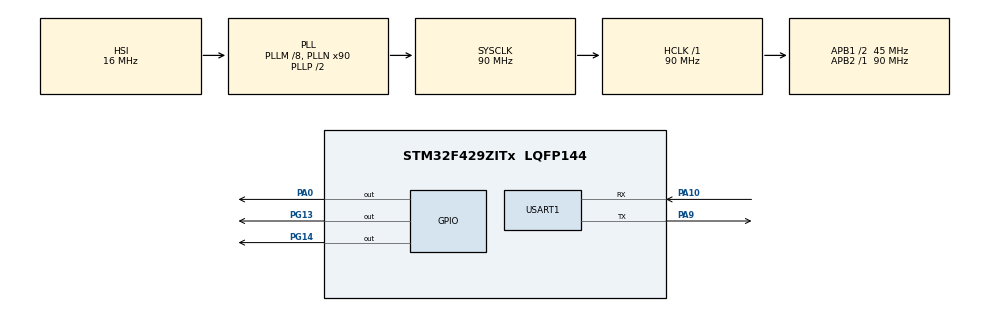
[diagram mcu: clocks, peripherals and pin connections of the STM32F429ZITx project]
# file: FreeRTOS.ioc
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FREERTOS.Queues01=myQueue01,16,uint16_t,0,Dynamic,NULL,NULL
FREERTOS.Tasks01=defaultTask,25,128,StartDefaultTask,Default,NULL,Dynamic,NULL,NULL;myTask,24,128,StartTask02,Default,NULL,Dynamic,NULL,NULL;myTask03,24,128,StartTask03,Default,NULL,Dynamic,NULL,NULL
Mcu.Family=STM32F4
Mcu.Name=STM32F429ZITx
Mcu.Package=LQFP144
NVIC.PriorityGroup=NVIC_PRIORITYGROUP_4
NVIC.TIM6_DAC_IRQn=true\:15\:0\:false\:false\:true\:false\:false\:true\:true
NVIC.TimeBase=TIM6_DAC_IRQn
NVIC.TimeBaseIP=TIM6
PA0/WKUP.Signal=GPIO_Output
PA10.Mode=Asynchronous
PA10.Signal=USART1_RX
PA9.Mode=Asynchronous
PA9.Signal=USART1_TX
PG13.Signal=GPIO_Output
PG14.Signal=GPIO_Output
PH0/OSC_IN.Mode=HSE-External-Oscillator
PH0/OSC_IN.Signal=RCC_OSC_IN
PH1/OSC_OUT.Mode=HSE-External-Oscillator
PH1/OSC_OUT.Signal=RCC_OSC_OUT
ProjectManager.HeapSize=0x200
ProjectManager.StackSize=0x400
ProjectManager.TargetToolchain=STM32CubeIDE
RCC.48MHZClocksFreq_Value=45000000
RCC.AHBFreq_Value=90000000
RCC.APB1CLKDivider=RCC_HCLK_DIV2
RCC.APB1Freq_Value=45000000
RCC.APB1TimFreq_Value=90000000
RCC.APB2Freq_Value=90000000
RCC.APB2TimFreq_Value=90000000
RCC.CortexFreq_Value=90000000
RCC.HCLKFreq_Value=90000000
RCC.HSE_VALUE=25000000
RCC.HSI_VALUE=16000000
RCC.LSE_VALUE=32768
RCC.PLLM=8
RCC.PLLN=90
RCC.SYSCLKFreq_VALUE=90000000
RCC.SYSCLKSource=RCC_SYSCLKSOURCE_PLLCLK
RCC.VCOOutputFreq_Value=180000000
USART1.VirtualMode=VM_ASYNC
VP_FREERTOS_VS_CMSIS_V2.Mode=CMSIS_V2
VP_SYS_VS_tim6.Mode=TIM6
board=custom

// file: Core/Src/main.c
/* USER CODE BEGIN Header */
/**
  ******************************************************************************
  * @file           : main.c
  * @brief          : Main program body
  ******************************************************************************
  * @attention
  *
  * Copyright (c) 2025 STMicroelectronics.
  * All rights reserved.
  *
  * This software is licensed under terms that can be found in the LICENSE file
  * in the root directory of this software component.
  * If no LICENSE file comes with this software, it is provided AS-IS.
  *
  ******************************************************************************
  */
/* USER CODE END Header */
#include "main.h"
#include "cmsis_os.h"

UART_HandleTypeDef huart1;

/* Definitions for defaultTask */
osThreadId_t defaultTaskHandle;
const osThreadAttr_t defaultTask_attributes = {
  .name = "defaultTask",
  .stack_size = 128 * 4,
  .priority = (osPriority_t) osPriorityNormal1,
};
/* Definitions for myTask */
osThreadId_t myTaskHandle;
const osThreadAttr_t myTask_attributes = {
  .name = "myTask",
  .stack_size = 128 * 4,
  .priority = (osPriority_t) osPriorityNormal,
};
/* Definitions for myTask03 */
osThreadId_t myTask03Handle;
const osThreadAttr_t myTask03_attributes = {
  .name = "myTask03",
  .stack_size = 128 * 4,
  .priority = (osPriority_t) osPriorityNormal,
};
/* Definitions for myQueue01 */
osMessageQueueId_t myQueue01Handle;
const osMessageQueueAttr_t myQueue01_attributes = {
  .name = "myQueue01"
};

void SystemClock_Config(void);
static void MX_GPIO_Init(void);
static void MX_USART1_UART_Init(void);
void StartDefaultTask(void *argument);
void StartTask02(void *argument);
void StartTask03(void *argument);

/* USER CODE BEGIN PFP */
void SendChar(char c) {
	uint8_t str[] = {c, '\r', '\n'};
	HAL_UART_Transmit(&huart1, str, 3, 10);
}
/* USER CODE END PFP */

int main(void)
{

  /* MCU Configuration--------------------------------------------------------*/

  /* Reset of all peripherals, Initializes the Flash interface and the Systick. */
  HAL_Init();

  /* Configure the system clock */
  SystemClock_Config();

  /* Initialize all configured peripherals */
  MX_GPIO_Init();
  MX_USART1_UART_Init();

  /* Init scheduler */
  osKernelInitialize();

  /* Create the queue(s) */
  /* creation of myQueue01 */
  myQueue01Handle = osMessageQueueNew (16, sizeof(uint16_t), &myQueue01_attributes);

  /* Create the thread(s) */
  /* creation of defaultTask */
  defaultTaskHandle = osThreadNew(StartDefaultTask, NULL, &defaultTask_attributes);

  /* creation of myTask */
  myTaskHandle = osThreadNew(StartTask02, NULL, &myTask_attributes);

  /* creation of myTask03 */
  myTask03Handle = osThreadNew(StartTask03, NULL, &myTask03_attributes);

  /* Start scheduler */
  osKernelStart();

  /* We should never get here as control is now taken by the scheduler */

  /* Infinite loop */
  while (1)
  {

  }
}

void SystemClock_Config(void)
{
  RCC_OscInitTypeDef RCC_OscInitStruct = {0};
  RCC_ClkInitTypeDef RCC_ClkInitStruct = {0};

  /** Configure the main internal regulator output voltage
  */
  __HAL_RCC_PWR_CLK_ENABLE();
  __HAL_PWR_VOLTAGESCALING_CONFIG(PWR_REGULATOR_VOLTAGE_SCALE3);

  /** Initializes the RCC Oscillators according to the specified parameters
  * in the RCC_OscInitTypeDef structure.
  */
  RCC_OscInitStruct.OscillatorType = RCC_OSCILLATORTYPE_HSI;
  RCC_OscInitStruct.HSIState = RCC_HSI_ON;
  RCC_OscInitStruct.HSICalibrationValue = RCC_HSICALIBRATION_DEFAULT;
  RCC_OscInitStruct.PLL.PLLState = RCC_PLL_ON;
  RCC_OscInitStruct.PLL.PLLSource = RCC_PLLSOURCE_HSI;
  RCC_OscInitStruct.PLL.PLLM = 8;
  RCC_OscInitStruct.PLL.PLLN = 90;
  RCC_OscInitStruct.PLL.PLLP = RCC_PLLP_DIV2;
  RCC_OscInitStruct.PLL.PLLQ = 4;
  if (HAL_RCC_OscConfig(&RCC_OscInitStruct) != HAL_OK)
  {
    Error_Handler();
  }

  /** Activate the Over-Drive mode
  */
  if (HAL_PWREx_EnableOverDrive() != HAL_OK)
  {
    Error_Handler();
  }

  /** Initializes the CPU, AHB and APB buses clocks
  */
  RCC_ClkInitStruct.ClockType = RCC_CLOCKTYPE_HCLK|RCC_CLOCKTYPE_SYSCLK
                              |RCC_CLOCKTYPE_PCLK1|RCC_CLOCKTYPE_PCLK2;
  RCC_ClkInitStruct.SYSCLKSource = RCC_SYSCLKSOURCE_PLLCLK;
  RCC_ClkInitStruct.AHBCLKDivider = RCC_SYSCLK_DIV1;
  RCC_ClkInitStruct.APB1CLKDivider = RCC_HCLK_DIV2;
  RCC_ClkInitStruct.APB2CLKDivider = RCC_HCLK_DIV1;

  if (HAL_RCC_ClockConfig(&RCC_ClkInitStruct, FLASH_LATENCY_2) != HAL_OK)
  {
    Error_Handler();
  }
}

static void MX_USART1_UART_Init(void)
{

  huart1.Instance = USART1;
  huart1.Init.BaudRate = 115200;
  huart1.Init.WordLength = UART_WORDLENGTH_8B;
  huart1.Init.StopBits = UART_STOPBITS_1;
  huart1.Init.Parity = UART_PARITY_NONE;
  huart1.Init.Mode = UART_MODE_TX_RX;
  huart1.Init.HwFlowCtl = UART_HWCONTROL_NONE;
  huart1.Init.OverSampling = UART_OVERSAMPLING_16;
  if (HAL_UART_Init(&huart1) != HAL_OK)
  {
    Error_Handler();
  }

}

static void MX_GPIO_Init(void)
{
  GPIO_InitTypeDef GPIO_InitStruct = {0};

  /* GPIO Ports Clock Enable */
  __HAL_RCC_GPIOH_CLK_ENABLE();
  __HAL_RCC_GPIOA_CLK_ENABLE();
  __HAL_RCC_GPIOG_CLK_ENABLE();

  /*Configure GPIO pin Output Level */
  HAL_GPIO_WritePin(GPIOA, GPIO_PIN_0, GPIO_PIN_RESET);

  /*Configure GPIO pin Output Level */
  HAL_GPIO_WritePin(GPIOG, GPIO_PIN_13|GPIO_PIN_14, GPIO_PIN_RESET);

  /*Configure GPIO pin : PA0 */
  GPIO_InitStruct.Pin = GPIO_PIN_0;
  GPIO_InitStruct.Mode = GPIO_MODE_OUTPUT_PP;
  GPIO_InitStruct.Pull = GPIO_NOPULL;
  GPIO_InitStruct.Speed = GPIO_SPEED_FREQ_LOW;
  HAL_GPIO_Init(GPIOA, &GPIO_InitStruct);

  /*Configure GPIO pins : PG13 PG14 */
  GPIO_InitStruct.Pin = GPIO_PIN_13|GPIO_PIN_14;
  GPIO_InitStruct.Mode = GPIO_MODE_OUTPUT_PP;
  GPIO_InitStruct.Pull = GPIO_NOPULL;
  GPIO_InitStruct.Speed = GPIO_SPEED_FREQ_LOW;
  HAL_GPIO_Init(GPIOG, &GPIO_InitStruct);

}

void StartDefaultTask(void *argument)
{
  /* USER CODE BEGIN 5 */
  /* Infinite loop */
  for(;;)
  {
    //SendChar('1');
    osDelay(200);
  }
  /* USER CODE END 5 */
}

void StartTask02(void *argument)
{
  /* USER CODE BEGIN StartTask02 */
  /* Infinite loop */
  for(;;)
  {
	  uint8_t res;
	  if(osMessageQueueGetCount(myQueue01Handle) > 0) {
		  osMessageQueueGet(myQueue01Handle, &res, NULL, 10);
		  if(res == 'X') {
			  HAL_UART_Transmit(&huart1, "Button press", 12, 100);
		  }
	  }
	  osDelay(1);
  }
  /* USER CODE END StartTask02 */
}

void StartTask03(void *argument)
{
  /* USER CODE BEGIN StartTask03 */
  /* Infinite loop */
  for(;;)
  {
	 if(HAL_GPIO_ReadPin(GPIOA, GPIO_PIN_0) == 1) {
		 uint8_t data = 'X';
		 osMessageQueuePut(myQueue01Handle, &data, 0, 10);
		 osDelay(200);
	 }
    osDelay(1);
  }
  /* USER CODE END StartTask03 */
}

void HAL_TIM_PeriodElapsedCallback(TIM_HandleTypeDef *htim)
{
  if (htim->Instance == TIM6) {
    HAL_IncTick();
  }
}

void Error_Handler(void)
{
  __disable_irq();
  while (1)
  {
  }
}
